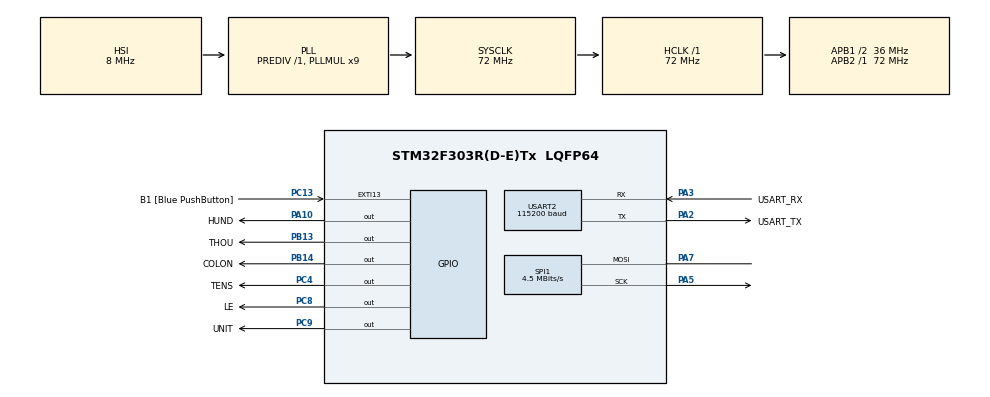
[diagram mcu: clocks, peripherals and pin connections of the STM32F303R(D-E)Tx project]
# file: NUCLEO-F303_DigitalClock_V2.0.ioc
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ADC1.Channel-0\#ChannelRegularConversion=ADC_CHANNEL_TEMPSENSOR
ADC1.Channel-1\#ChannelRegularConversion=ADC_CHANNEL_VREFINT
ADC1.ContinuousConvMode=ENABLE
ADC1.DMAContinuousRequests=ENABLE
ADC1.NbrOfConversion=2
ADC1.NbrOfConversionFlag=1
ADC1.Offset-0\#ChannelRegularConversion=0
ADC1.Offset-1\#ChannelRegularConversion=0
ADC1.OffsetNumber-0\#ChannelRegularConversion=ADC_OFFSET_NONE
ADC1.OffsetNumber-1\#ChannelRegularConversion=ADC_OFFSET_NONE
ADC1.Rank-0\#ChannelRegularConversion=1
ADC1.Rank-1\#ChannelRegularConversion=2
ADC1.SamplingTime-0\#ChannelRegularConversion=ADC_SAMPLETIME_601CYCLES_5
ADC1.SamplingTime-1\#ChannelRegularConversion=ADC_SAMPLETIME_601CYCLES_5
ADC1.master=1
Dma.ADC1.0.Direction=DMA_PERIPH_TO_MEMORY
Dma.ADC1.0.Instance=DMA1_Channel1
Dma.ADC1.0.MemDataAlignment=DMA_MDATAALIGN_HALFWORD
Dma.ADC1.0.MemInc=DMA_MINC_ENABLE
Dma.ADC1.0.Mode=DMA_NORMAL
Dma.ADC1.0.PeriphDataAlignment=DMA_PDATAALIGN_HALFWORD
Dma.ADC1.0.PeriphInc=DMA_PINC_DISABLE
Dma.ADC1.0.Priority=DMA_PRIORITY_LOW
Dma.Request0=ADC1
Mcu.Family=STM32F3
Mcu.Name=STM32F303R(D-E)Tx
Mcu.Package=LQFP64
NVIC.DMA1_Channel1_IRQn=true\:0\:0\:false\:false\:true\:false\:true\:true
NVIC.PriorityGroup=NVIC_PRIORITYGROUP_0
NVIC.RTC_Alarm_IRQn=true\:0\:0\:false\:false\:true\:true\:true\:true
NVIC.TIM3_IRQn=true\:0\:0\:false\:false\:true\:true\:true\:true
PA10.GPIO_Label=HUND
PA10.Signal=GPIO_Output
PA13.GPIO_Label=TMS
PA13.Mode=Serial_Wire
PA13.Signal=SYS_JTMS-SWDIO
PA14.GPIO_Label=TCK
PA14.Mode=Serial_Wire
PA14.Signal=SYS_JTCK-SWCLK
PA2.GPIO_Label=USART_TX
PA2.GPIO_Mode=GPIO_MODE_AF_PP
PA2.GPIO_PuPd=GPIO_NOPULL
PA2.GPIO_Speed=GPIO_SPEED_FREQ_LOW
PA2.Mode=Asynchronous
PA2.Signal=USART2_TX
PA3.GPIO_Label=USART_RX
PA3.GPIO_Mode=GPIO_MODE_AF_PP
PA3.GPIO_PuPd=GPIO_NOPULL
PA3.GPIO_Speed=GPIO_SPEED_FREQ_LOW
PA3.Mode=Asynchronous
PA3.Signal=USART2_RX
PA5.Mode=Simplex_Bidirectional_Master
PA5.Signal=SPI1_SCK
PA7.Mode=Simplex_Bidirectional_Master
PA7.Signal=SPI1_MOSI
PB13.GPIO_Label=THOU
PB13.Signal=GPIO_Output
PB14.GPIO_Label=COLON
PB14.Signal=GPIO_Output
PB3.GPIO_Label=SWO
PB3.Signal=SYS_JTDO-TRACESWO
PC13.GPIO_Label=B1 [Blue PushButton]
PC13.GPIO_ModeDefaultEXTI=GPIO_MODE_IT_FALLING
PC13.Signal=GPXTI13
PC14-OSC32_IN.Mode=LSE-External-Oscillator
PC14-OSC32_IN.Signal=RCC_OSC32_IN
PC15-OSC32_OUT.Mode=LSE-External-Oscillator
PC15-OSC32_OUT.Signal=RCC_OSC32_OUT
PC4.GPIO_Label=TENS
PC4.Signal=GPIO_Output
PC8.GPIO_Label=LE
PC8.Signal=GPIO_Output
PC9.GPIO_Label=UNIT
PC9.Signal=GPIO_Output
PF0-OSC_IN.Mode=HSE-External-Clock-Source
PF0-OSC_IN.Signal=RCC_OSC_IN
PF1-OSC_OUT.Signal=RCC_OSC_OUT
ProjectManager.HeapSize=0x200
ProjectManager.StackSize=0x400
ProjectManager.TargetToolchain=CMake
RCC.AHBFreq_Value=72000000
RCC.APB1CLKDivider=RCC_HCLK_DIV2
RCC.APB1Freq_Value=36000000
RCC.APB1TimFreq_Value=72000000
RCC.APB2Freq_Value=72000000
RCC.APB2TimFreq_Value=72000000
RCC.CortexFreq_Value=72000000
RCC.HCLKFreq_Value=72000000
RCC.HSE_VALUE=8000000
RCC.HSI_VALUE=8000000
RCC.PLLM=8
RCC.PLLMUL=RCC_PLL_MUL9
RCC.PLLN=336
RCC.PLLP=RCC_PLLP_DIV4
RCC.PLLQ=7
RCC.RCC_PLLsource_Clock_Source_FROM_HSE=RCC_HSE_PREDIV_DIV2
RCC.RTCClockSelection=RCC_RTCCLKSOURCE_LSE
RCC.SYSCLKFreq_VALUE=72000000
RCC.SYSCLKSourceVirtual=RCC_SYSCLKSOURCE_PLLCLK
RCC.USBFreq_Value=72000000
RTC.Alarm-Alarm\ A=RTC_ALARM_A
RTC.AlarmMaskDateWeekDay-Alarm\ A=RTC_ALARMMASK_DATEWEEKDAY
RTC.AlarmMaskHours-Alarm\ A=RTC_ALARMMASK_HOURS
RTC.AlarmMaskMinutes-Alarm\ A=RTC_ALARMMASK_MINUTES
RTC.AlarmMaskSeconds-Alarm\ A=RTC_ALARMMASK_SECONDS
SPI1.BaudRatePrescaler=SPI_BAUDRATEPRESCALER_16
SPI1.CalculateBaudRate=4.5 MBits/s
SPI1.DataSize=SPI_DATASIZE_8BIT
SPI1.Direction=SPI_DIRECTION_1LINE
SPI1.Mode=SPI_MODE_MASTER
SPI1.VirtualType=VM_MASTER
TIM3.Period=500-1
TIM3.Prescaler=720-1
USART2.BaudRate=115200
USART2.VirtualMode-Asynchronous=VM_ASYNC
VP_ADC1_TempSens_Input.Mode=IN-TempSens
VP_ADC1_Vref_Input.Mode=IN-Vrefint
VP_RTC_VS_RTC_Activate.Mode=RTC_Enabled
VP_RTC_VS_RTC_Alarm_A_Intern.Mode=Alarm A
VP_RTC_VS_RTC_Calendar.Mode=RTC_Calendar
VP_TIM3_VS_ClockSourceINT.Mode=Internal
board=NUCLEO-F303RE

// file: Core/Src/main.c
/* USER CODE BEGIN Header */
/**
  ******************************************************************************
  * @file           : main.c
  * @brief          : Main program body
  ******************************************************************************
  * @attention
  *
  * Copyright (c) 2026 STMicroelectronics.
  * All rights reserved.
  *
  * This software is licensed under terms that can be found in the LICENSE file
  * in the root directory of this software component.
  * If no LICENSE file comes with this software, it is provided AS-IS.
  *
  ******************************************************************************
  */
/* USER CODE END Header */
#include "main.h"

/* USER CODE BEGIN Includes */
#include "internal_temp_app.h"
#include "clock_app.h"
/* USER CODE END Includes */

ADC_HandleTypeDef hadc1;
DMA_HandleTypeDef hdma_adc1;

RTC_HandleTypeDef hrtc;

SPI_HandleTypeDef hspi1;

TIM_HandleTypeDef htim3;

UART_HandleTypeDef huart2;

/* USER CODE BEGIN PV */
volatile _Bool adcIsConversionCompleted = 0;
/* USER CODE END PV */

void SystemClock_Config(void);
static void MX_GPIO_Init(void);
static void MX_DMA_Init(void);
static void MX_SPI1_Init(void);
static void MX_USART2_UART_Init(void);
static void MX_RTC_Init(void);
static void MX_TIM3_Init(void);
static void MX_ADC1_Init(void);

int main(void)
{

  /* MCU Configuration--------------------------------------------------------*/

  /* Reset of all peripherals, Initializes the Flash interface and the Systick. */
  HAL_Init();

  /* Configure the system clock */
  SystemClock_Config();

  /* Initialize all configured peripherals */
  MX_GPIO_Init();
  MX_DMA_Init();
  MX_SPI1_Init();
  MX_USART2_UART_Init();
  MX_RTC_Init();
  MX_TIM3_Init();
  MX_ADC1_Init();
  /* USER CODE BEGIN 2 */
  Internal_Temp_App_Init(&hadc1);
  Clock_App_Init(&hrtc, &hspi1);
  HAL_TIM_Base_Start_IT(&htim3);
  /* USER CODE END 2 */

  /* Infinite loop */
  /* USER CODE BEGIN WHILE */
  while (1)
  {
    __WFI();
    Internal_Temp_App_Task();
    Clock_App_Task();
    /* USER CODE END WHILE */

  }
}

void SystemClock_Config(void)
{
  RCC_OscInitTypeDef RCC_OscInitStruct = {0};
  RCC_ClkInitTypeDef RCC_ClkInitStruct = {0};
  RCC_PeriphCLKInitTypeDef PeriphClkInit = {0};

  /** Configure LSE Drive Capability
  */
  HAL_PWR_EnableBkUpAccess();
  __HAL_RCC_LSEDRIVE_CONFIG(RCC_LSEDRIVE_LOW);

  /** Initializes the RCC Oscillators according to the specified parameters
  * in the RCC_OscInitTypeDef structure.
  */
  RCC_OscInitStruct.OscillatorType = RCC_OSCILLATORTYPE_HSI|RCC_OSCILLATORTYPE_LSE;
  RCC_OscInitStruct.LSEState = RCC_LSE_ON;
  RCC_OscInitStruct.HSIState = RCC_HSI_ON;
  RCC_OscInitStruct.HSICalibrationValue = RCC_HSICALIBRATION_DEFAULT;
  RCC_OscInitStruct.PLL.PLLState = RCC_PLL_ON;
  RCC_OscInitStruct.PLL.PLLSource = RCC_PLLSOURCE_HSI;
  RCC_OscInitStruct.PLL.PLLMUL = RCC_PLL_MUL9;
  RCC_OscInitStruct.PLL.PREDIV = RCC_PREDIV_DIV1;
  if (HAL_RCC_OscConfig(&RCC_OscInitStruct) != HAL_OK)
  {
    Error_Handler();
  }

  /** Initializes the CPU, AHB and APB buses clocks
  */
  RCC_ClkInitStruct.ClockType = RCC_CLOCKTYPE_HCLK|RCC_CLOCKTYPE_SYSCLK
                              |RCC_CLOCKTYPE_PCLK1|RCC_CLOCKTYPE_PCLK2;
  RCC_ClkInitStruct.SYSCLKSource = RCC_SYSCLKSOURCE_PLLCLK;
  RCC_ClkInitStruct.AHBCLKDivider = RCC_SYSCLK_DIV1;
  RCC_ClkInitStruct.APB1CLKDivider = RCC_HCLK_DIV2;
  RCC_ClkInitStruct.APB2CLKDivider = RCC_HCLK_DIV1;

  if (HAL_RCC_ClockConfig(&RCC_ClkInitStruct, FLASH_LATENCY_2) != HAL_OK)
  {
    Error_Handler();
  }
  PeriphClkInit.PeriphClockSelection = RCC_PERIPHCLK_USART2|RCC_PERIPHCLK_RTC
                              |RCC_PERIPHCLK_ADC12|RCC_PERIPHCLK_TIM34;
  PeriphClkInit.Usart2ClockSelection = RCC_USART2CLKSOURCE_PCLK1;
  PeriphClkInit.Adc12ClockSelection = RCC_ADC12PLLCLK_DIV1;
  PeriphClkInit.RTCClockSelection = RCC_RTCCLKSOURCE_LSE;
  PeriphClkInit.Tim34ClockSelection = RCC_TIM34CLK_HCLK;
  if (HAL_RCCEx_PeriphCLKConfig(&PeriphClkInit) != HAL_OK)
  {
    Error_Handler();
  }
}

static void MX_ADC1_Init(void)
{

  ADC_MultiModeTypeDef multimode = {0};
  ADC_ChannelConfTypeDef sConfig = {0};

  /** Common config
  */
  hadc1.Instance = ADC1;
  hadc1.Init.ClockPrescaler = ADC_CLOCK_ASYNC_DIV1;
  hadc1.Init.Resolution = ADC_RESOLUTION_12B;
  hadc1.Init.ScanConvMode = ADC_SCAN_ENABLE;
  hadc1.Init.ContinuousConvMode = ENABLE;
  hadc1.Init.DiscontinuousConvMode = DISABLE;
  hadc1.Init.ExternalTrigConvEdge = ADC_EXTERNALTRIGCONVEDGE_NONE;
  hadc1.Init.ExternalTrigConv = ADC_SOFTWARE_START;
  hadc1.Init.DataAlign = ADC_DATAALIGN_RIGHT;
  hadc1.Init.NbrOfConversion = 2;
  hadc1.Init.DMAContinuousRequests = ENABLE;
  hadc1.Init.EOCSelection = ADC_EOC_SINGLE_CONV;
  hadc1.Init.LowPowerAutoWait = DISABLE;
  hadc1.Init.Overrun = ADC_OVR_DATA_OVERWRITTEN;
  if (HAL_ADC_Init(&hadc1) != HAL_OK)
  {
    Error_Handler();
  }

  /** Configure the ADC multi-mode
  */
  multimode.Mode = ADC_MODE_INDEPENDENT;
  if (HAL_ADCEx_MultiModeConfigChannel(&hadc1, &multimode) != HAL_OK)
  {
    Error_Handler();
  }

  /** Configure Regular Channel
  */
  sConfig.Channel = ADC_CHANNEL_TEMPSENSOR;
  sConfig.Rank = ADC_REGULAR_RANK_1;
  sConfig.SingleDiff = ADC_SINGLE_ENDED;
  sConfig.SamplingTime = ADC_SAMPLETIME_601CYCLES_5;
  sConfig.OffsetNumber = ADC_OFFSET_NONE;
  sConfig.Offset = 0;
  if (HAL_ADC_ConfigChannel(&hadc1, &sConfig) != HAL_OK)
  {
    Error_Handler();
  }

  /** Configure Regular Channel
  */
  sConfig.Channel = ADC_CHANNEL_VREFINT;
  sConfig.Rank = ADC_REGULAR_RANK_2;
  if (HAL_ADC_ConfigChannel(&hadc1, &sConfig) != HAL_OK)
  {
    Error_Handler();
  }

}

static void MX_RTC_Init(void)
{

  RTC_TimeTypeDef sTime = {0};
  RTC_DateTypeDef sDate = {0};
  RTC_AlarmTypeDef sAlarm = {0};

  /** Initialize RTC Only
  */
  hrtc.Instance = RTC;
  hrtc.Init.HourFormat = RTC_HOURFORMAT_24;
  hrtc.Init.AsynchPrediv = 127;
  hrtc.Init.SynchPrediv = 255;
  hrtc.Init.OutPut = RTC_OUTPUT_DISABLE;
  hrtc.Init.OutPutPolarity = RTC_OUTPUT_POLARITY_HIGH;
  hrtc.Init.OutPutType = RTC_OUTPUT_TYPE_OPENDRAIN;
  if (HAL_RTC_Init(&hrtc) != HAL_OK)
  {
    Error_Handler();
  }

  /** Initialize RTC and set the Time and Date
  */
  sTime.Hours = 0x0;
  sTime.Minutes = 0x0;
  sTime.Seconds = 0x0;
  sTime.DayLightSaving = RTC_DAYLIGHTSAVING_NONE;
  sTime.StoreOperation = RTC_STOREOPERATION_RESET;
  if (HAL_RTC_SetTime(&hrtc, &sTime, RTC_FORMAT_BCD) != HAL_OK)
  {
    Error_Handler();
  }
  sDate.WeekDay = RTC_WEEKDAY_MONDAY;
  sDate.Month = RTC_MONTH_JANUARY;
  sDate.Date = 0x1;
  sDate.Year = 0x0;

  if (HAL_RTC_SetDate(&hrtc, &sDate, RTC_FORMAT_BCD) != HAL_OK)
  {
    Error_Handler();
  }

  /** Enable the Alarm A
  */
  sAlarm.AlarmTime.Hours = 0x0;
  sAlarm.AlarmTime.Minutes = 0x0;
  sAlarm.AlarmTime.Seconds = 0x0;
  sAlarm.AlarmTime.SubSeconds = 0x0;
  sAlarm.AlarmTime.DayLightSaving = RTC_DAYLIGHTSAVING_NONE;
  sAlarm.AlarmTime.StoreOperation = RTC_STOREOPERATION_RESET;
  sAlarm.AlarmMask = RTC_ALARMMASK_ALL;
  sAlarm.AlarmSubSecondMask = RTC_ALARMSUBSECONDMASK_ALL;
  sAlarm.AlarmDateWeekDaySel = RTC_ALARMDATEWEEKDAYSEL_DATE;
  sAlarm.AlarmDateWeekDay = 0x1;
  sAlarm.Alarm = RTC_ALARM_A;
  if (HAL_RTC_SetAlarm_IT(&hrtc, &sAlarm, RTC_FORMAT_BCD) != HAL_OK)
  {
    Error_Handler();
  }

}

static void MX_SPI1_Init(void)
{

  /* SPI1 parameter configuration*/
  hspi1.Instance = SPI1;
  hspi1.Init.Mode = SPI_MODE_MASTER;
  hspi1.Init.Direction = SPI_DIRECTION_1LINE;
  hspi1.Init.DataSize = SPI_DATASIZE_8BIT;
  hspi1.Init.CLKPolarity = SPI_POLARITY_LOW;
  hspi1.Init.CLKPhase = SPI_PHASE_1EDGE;
  hspi1.Init.NSS = SPI_NSS_SOFT;
  hspi1.Init.BaudRatePrescaler = SPI_BAUDRATEPRESCALER_16;
  hspi1.Init.FirstBit = SPI_FIRSTBIT_MSB;
  hspi1.Init.TIMode = SPI_TIMODE_DISABLE;
  hspi1.Init.CRCCalculation = SPI_CRCCALCULATION_DISABLE;
  hspi1.Init.CRCPolynomial = 7;
  hspi1.Init.CRCLength = SPI_CRC_LENGTH_DATASIZE;
  hspi1.Init.NSSPMode = SPI_NSS_PULSE_ENABLE;
  if (HAL_SPI_Init(&hspi1) != HAL_OK)
  {
    Error_Handler();
  }

}

static void MX_TIM3_Init(void)
{

  TIM_ClockConfigTypeDef sClockSourceConfig = {0};
  TIM_MasterConfigTypeDef sMasterConfig = {0};

  htim3.Instance = TIM3;
  htim3.Init.Prescaler = 720-1;
  htim3.Init.CounterMode = TIM_COUNTERMODE_UP;
  htim3.Init.Period = 500-1;
  htim3.Init.ClockDivision = TIM_CLOCKDIVISION_DIV1;
  htim3.Init.AutoReloadPreload = TIM_AUTORELOAD_PRELOAD_DISABLE;
  if (HAL_TIM_Base_Init(&htim3) != HAL_OK)
  {
    Error_Handler();
  }
  sClockSourceConfig.ClockSource = TIM_CLOCKSOURCE_INTERNAL;
  if (HAL_TIM_ConfigClockSource(&htim3, &sClockSourceConfig) != HAL_OK)
  {
    Error_Handler();
  }
  sMasterConfig.MasterOutputTrigger = TIM_TRGO_RESET;
  sMasterConfig.MasterSlaveMode = TIM_MASTERSLAVEMODE_DISABLE;
  if (HAL_TIMEx_MasterConfigSynchronization(&htim3, &sMasterConfig) != HAL_OK)
  {
    Error_Handler();
  }

}

static void MX_USART2_UART_Init(void)
{

  huart2.Instance = USART2;
  huart2.Init.BaudRate = 115200;
  huart2.Init.WordLength = UART_WORDLENGTH_8B;
  huart2.Init.StopBits = UART_STOPBITS_1;
  huart2.Init.Parity = UART_PARITY_NONE;
  huart2.Init.Mode = UART_MODE_TX_RX;
  huart2.Init.HwFlowCtl = UART_HWCONTROL_NONE;
  huart2.Init.OverSampling = UART_OVERSAMPLING_16;
  huart2.Init.OneBitSampling = UART_ONE_BIT_SAMPLE_DISABLE;
  huart2.AdvancedInit.AdvFeatureInit = UART_ADVFEATURE_NO_INIT;
  if (HAL_UART_Init(&huart2) != HAL_OK)
  {
    Error_Handler();
  }

}

static void MX_DMA_Init(void)
{

  /* DMA controller clock enable */
  __HAL_RCC_DMA1_CLK_ENABLE();

  /* DMA interrupt init */
  /* DMA1_Channel1_IRQn interrupt configuration */
  HAL_NVIC_SetPriority(DMA1_Channel1_IRQn, 0, 0);
  HAL_NVIC_EnableIRQ(DMA1_Channel1_IRQn);

}

static void MX_GPIO_Init(void)
{
  GPIO_InitTypeDef GPIO_InitStruct = {0};

  /* GPIO Ports Clock Enable */
  __HAL_RCC_GPIOC_CLK_ENABLE();
  __HAL_RCC_GPIOF_CLK_ENABLE();
  __HAL_RCC_GPIOA_CLK_ENABLE();
  __HAL_RCC_GPIOB_CLK_ENABLE();

  /*Configure GPIO pin Output Level */
  HAL_GPIO_WritePin(GPIOC, TENS_Pin|LE_Pin|UNIT_Pin, GPIO_PIN_RESET);

  /*Configure GPIO pin Output Level */
  HAL_GPIO_WritePin(GPIOB, THOU_Pin|COLON_Pin, GPIO_PIN_RESET);

  /*Configure GPIO pin Output Level */
  HAL_GPIO_WritePin(HUND_GPIO_Port, HUND_Pin, GPIO_PIN_RESET);

  /*Configure GPIO pin : B1_Pin */
  GPIO_InitStruct.Pin = B1_Pin;
  GPIO_InitStruct.Mode = GPIO_MODE_IT_FALLING;
  GPIO_InitStruct.Pull = GPIO_NOPULL;
  HAL_GPIO_Init(B1_GPIO_Port, &GPIO_InitStruct);

  /*Configure GPIO pins : TENS_Pin LE_Pin UNIT_Pin */
  GPIO_InitStruct.Pin = TENS_Pin|LE_Pin|UNIT_Pin;
  GPIO_InitStruct.Mode = GPIO_MODE_OUTPUT_PP;
  GPIO_InitStruct.Pull = GPIO_NOPULL;
  GPIO_InitStruct.Speed = GPIO_SPEED_FREQ_LOW;
  HAL_GPIO_Init(GPIOC, &GPIO_InitStruct);

  /*Configure GPIO pins : THOU_Pin COLON_Pin */
  GPIO_InitStruct.Pin = THOU_Pin|COLON_Pin;
  GPIO_InitStruct.Mode = GPIO_MODE_OUTPUT_PP;
  GPIO_InitStruct.Pull = GPIO_NOPULL;
  GPIO_InitStruct.Speed = GPIO_SPEED_FREQ_LOW;
  HAL_GPIO_Init(GPIOB, &GPIO_InitStruct);

  /*Configure GPIO pin : HUND_Pin */
  GPIO_InitStruct.Pin = HUND_Pin;
  GPIO_InitStruct.Mode = GPIO_MODE_OUTPUT_PP;
  GPIO_InitStruct.Pull = GPIO_NOPULL;
  GPIO_InitStruct.Speed = GPIO_SPEED_FREQ_LOW;
  HAL_GPIO_Init(HUND_GPIO_Port, &GPIO_InitStruct);

}

/* USER CODE BEGIN 4 */
void HAL_ADC_ConvCpltCallback(ADC_HandleTypeDef *hadc)
{
    if (hadc->Instance == ADC1)
    {
        adcIsConversionCompleted = 1;
    }
}
/* USER CODE END 4 */

void Error_Handler(void)
{
  __disable_irq();
  while (1)
  {
  }
}
